CM_ "AUTOGENERATED FILE, DO NOT EDIT";

CM_ "Imported file _toyota_2017.dbc starts here";
VERSION ""

NS_ :

BS_:

BU_: XXX DSU HCU EPS IPAS CGW BGM

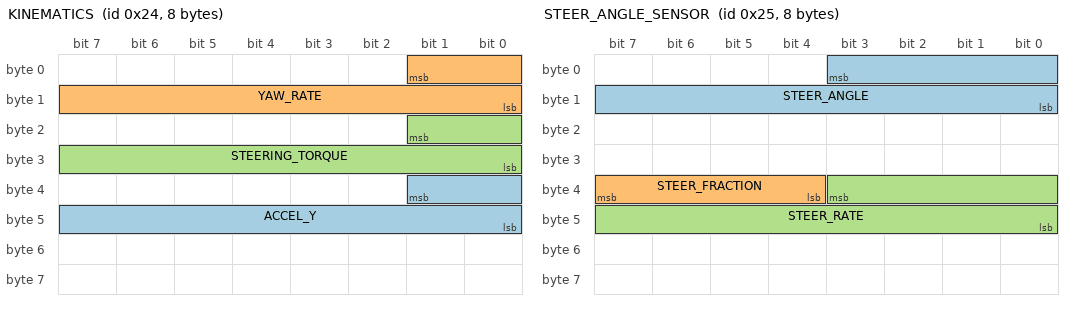
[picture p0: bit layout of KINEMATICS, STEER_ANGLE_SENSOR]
BO_ 36 KINEMATICS: 8 XXX
 SG_ ACCEL_Y : 33|10@0+ (0.03589,-18.375) [0|65535] "m/s^2" XXX
 SG_ YAW_RATE : 1|10@0+ (0.244,-125) [0|65535] "deg/s" XXX
 SG_ STEERING_TORQUE : 17|10@0+ (1,-512) [0|65535] "" XXX

BO_ 37 STEER_ANGLE_SENSOR: 8 XXX
 SG_ STEER_ANGLE : 3|12@0- (1.5,0) [-500|500] "deg" XXX
 SG_ STEER_FRACTION : 39|4@0- (0.1,0) [-0.7|0.7] "deg" XXX
 SG_ STEER_RATE : 35|12@0- (1,0) [-2000|2000] "deg/s" XXX

BO_ 166 BRAKE: 8 XXX
 SG_ BRAKE_AMOUNT : 7|8@0+ (1,0) [0|255] "" XXX
 SG_ BRAKE_PEDAL : 23|8@0+ (1,0) [0|255] "" XXX

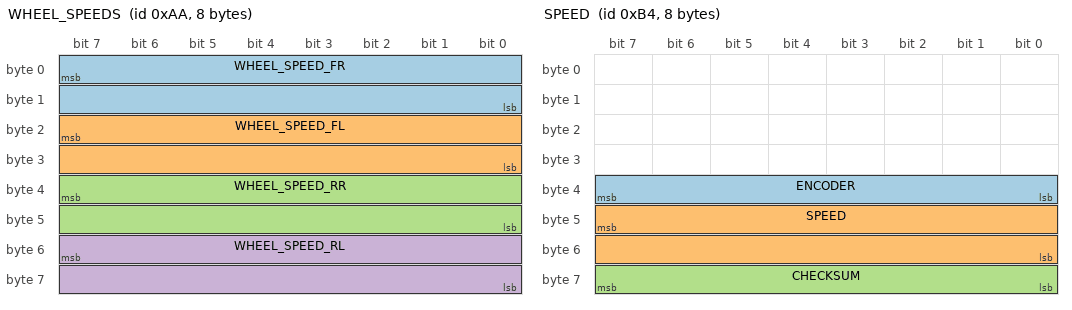
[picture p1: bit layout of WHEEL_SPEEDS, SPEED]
BO_ 170 WHEEL_SPEEDS: 8 XXX
 SG_ WHEEL_SPEED_FR : 7|16@0+ (0.01,-67.67) [0|250] "km/h" XXX
 SG_ WHEEL_SPEED_FL : 23|16@0+ (0.01,-67.67) [0|250] "km/h" XXX
 SG_ WHEEL_SPEED_RR : 39|16@0+ (0.01,-67.67) [0|250] "km/h" XXX
 SG_ WHEEL_SPEED_RL : 55|16@0+ (0.01,-67.67) [0|250] "km/h" XXX

BO_ 180 SPEED: 8 XXX
 SG_ ENCODER : 39|8@0+ (1,0) [0|255] "" XXX
 SG_ SPEED : 47|16@0+ (0.01,0) [0|250] "km/h" XXX
 SG_ CHECKSUM : 63|8@0+ (1,0) [0|255] "" XXX

BO_ 353 DSU_SPEED: 7 XXX
 SG_ FORWARD_SPEED : 15|16@0- (0.00390625,-30) [0|255] "km/h" XXX

BO_ 452 ENGINE_RPM: 8 CGW
 SG_ RPM : 7|16@0- (0.78125,0) [0|0] "rpm" SCS

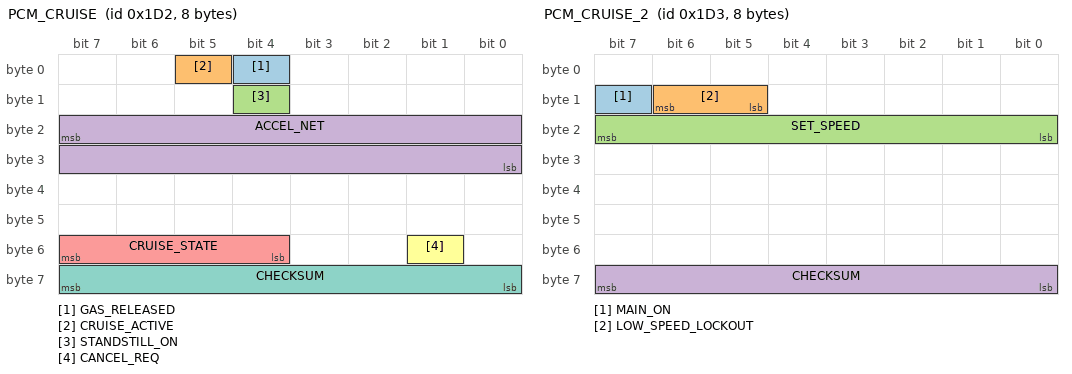
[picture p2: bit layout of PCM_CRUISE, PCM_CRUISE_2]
BO_ 466 PCM_CRUISE: 8 XXX
 SG_ GAS_RELEASED : 4|1@0+ (1,0) [0|1] "" XXX
 SG_ CRUISE_ACTIVE : 5|1@0+ (1,0) [0|1] "" XXX
 SG_ STANDSTILL_ON : 12|1@0+ (1,0) [0|1] "" XXX
 SG_ ACCEL_NET : 23|16@0- (0.001,0) [-20|20] "m/s^2" XXX
 SG_ CRUISE_STATE : 55|4@0+ (1,0) [0|15] "" XXX
 SG_ CANCEL_REQ : 49|1@1+ (1,0) [0|1] "" XXX
 SG_ CHECKSUM : 63|8@0+ (1,0) [0|255] "" XXX

BO_ 467 PCM_CRUISE_2: 8 XXX
 SG_ MAIN_ON : 15|1@0+ (1,0) [0|1] "" XXX
 SG_ LOW_SPEED_LOCKOUT : 14|2@0+ (1,0) [0|3] "" XXX
 SG_ SET_SPEED : 23|8@0+ (1,0) [0|255] "km/h" XXX
 SG_ CHECKSUM : 63|8@0+ (1,0) [0|255] "" XXX

BO_ 552 ACCELEROMETER: 8 XXX
 SG_ ACCEL_Z : 22|15@0- (1,0) [0|32767] "m/s^2" XXX
 SG_ ACCEL_X : 6|15@0- (0.001,0) [-20|20] "m/s^2" XXX

BO_ 560 BRAKE_2: 7 XXX
 SG_ BRAKE_PRESSED : 26|1@0+ (1,0) [0|1] "" XXX

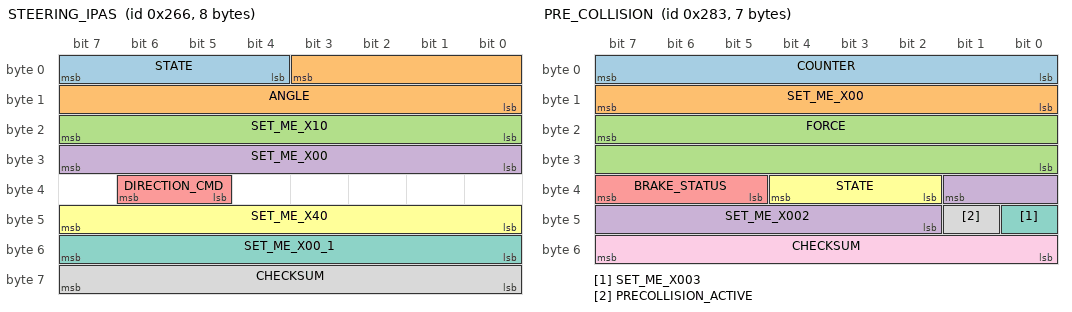
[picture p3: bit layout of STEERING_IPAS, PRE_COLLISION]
BO_ 614 STEERING_IPAS: 8 IPAS
 SG_ STATE : 7|4@0+ (1,0) [0|15] "" XXX
 SG_ ANGLE : 3|12@0- (1.5,0) [-510|510] "deg" XXX
 SG_ SET_ME_X10 : 23|8@0+ (1,0) [0|255] "" XXX
 SG_ SET_ME_X00 : 31|8@0+ (1,0) [0|255] "" XXX
 SG_ DIRECTION_CMD : 38|2@0+ (1,0) [0|3] "" XXX
 SG_ SET_ME_X40 : 47|8@0+ (1,0) [0|255] "" XXX
 SG_ SET_ME_X00_1 : 55|8@0+ (1,0) [0|255] "" XXX
 SG_ CHECKSUM : 63|8@0+ (1,0) [0|255] "" XXX

BO_ 643 PRE_COLLISION: 7 DSU
 SG_ COUNTER : 7|8@0+ (1,0) [0|255] "" XXX
 SG_ SET_ME_X00 : 15|8@0+ (1,0) [0|255] "" XXX
 SG_ FORCE : 23|16@0- (2,0) [0|255] "N" XXX
 SG_ SET_ME_X002 : 33|8@0+ (1,0) [0|3] "" XXX
 SG_ BRAKE_STATUS : 39|3@0+ (1,0) [0|255] "" XXX
 SG_ STATE : 36|3@0+ (1,0) [0|255] "" XXX
 SG_ SET_ME_X003 : 40|1@0+ (1,0) [0|1] "" XXX
 SG_ PRECOLLISION_ACTIVE : 41|1@0+ (1,0) [0|255] "" XXX
 SG_ CHECKSUM : 55|8@0+ (1,0) [0|255] "" XXX

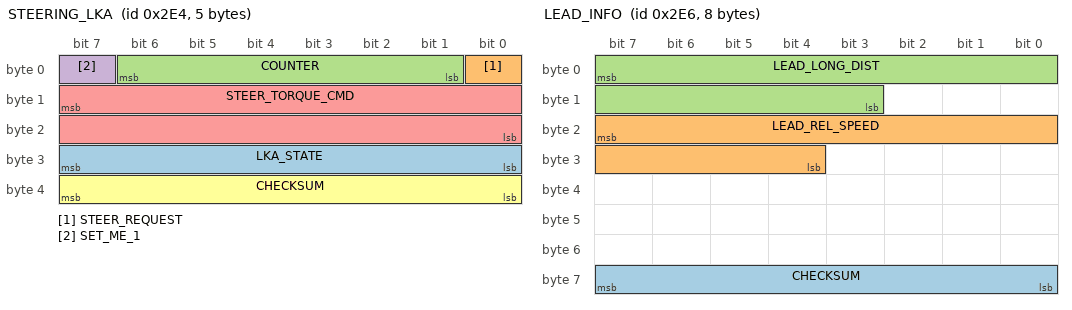
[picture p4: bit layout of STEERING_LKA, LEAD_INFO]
BO_ 740 STEERING_LKA: 5 XXX
 SG_ LKA_STATE : 31|8@0+ (1,0) [0|255] "" XXX
 SG_ STEER_REQUEST : 0|1@0+ (1,0) [0|1] "" XXX
 SG_ COUNTER : 6|6@0+ (1,0) [0|63] "" XXX
 SG_ SET_ME_1 : 7|1@0+ (1,0) [0|1] "" XXX
 SG_ STEER_TORQUE_CMD : 15|16@0- (1,0) [0|65535] "" XXX
 SG_ CHECKSUM : 39|8@0+ (1,0) [0|255] "" XXX

BO_ 742 LEAD_INFO: 8 DSU
 SG_ CHECKSUM : 63|8@0+ (1,0) [0|255] "" HCU
 SG_ LEAD_REL_SPEED : 23|12@0- (0.025,0) [-100|100] "m/s" HCU
 SG_ LEAD_LONG_DIST : 7|13@0+ (0.05,0) [0|300] "m" HCU

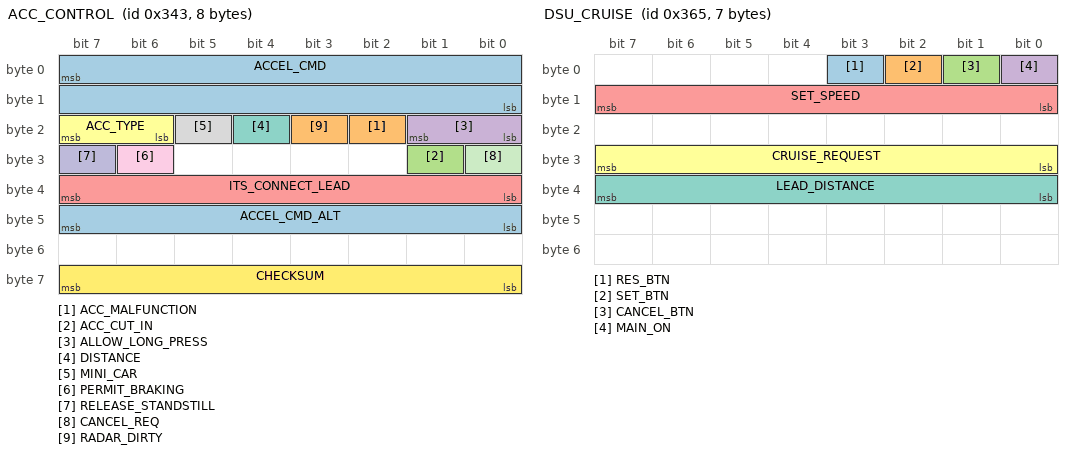
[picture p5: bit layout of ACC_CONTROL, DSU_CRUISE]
BO_ 835 ACC_CONTROL: 8 DSU
 SG_ ACCEL_CMD : 7|16@0- (0.001,0) [-20|20] "m/s^2" HCU
 SG_ ACC_MALFUNCTION : 18|1@0+ (1,0) [0|0] "" XXX
 SG_ ACC_CUT_IN : 25|1@0+ (1,0) [0|1] "" XXX
 SG_ ALLOW_LONG_PRESS : 17|2@0+ (1,0) [0|2] "" XXX
 SG_ ITS_CONNECT_LEAD : 39|8@0+ (1,0) [0|1] "" Vector__XXX
 SG_ ACC_TYPE : 23|2@0+ (1,0) [0|3] "" HCU
 SG_ DISTANCE : 20|1@0+ (1,0) [0|1] "" XXX
 SG_ MINI_CAR : 21|1@0+ (1,0) [0|1] "" XXX
 SG_ PERMIT_BRAKING : 30|1@0+ (1,0) [0|1] "" HCU
 SG_ RELEASE_STANDSTILL : 31|1@0+ (1,0) [0|1] "" HCU
 SG_ CANCEL_REQ : 24|1@0+ (1,0) [0|1] "" HCU
 SG_ CHECKSUM : 63|8@0+ (1,0) [0|255] "" XXX
 SG_ ACCEL_CMD_ALT : 47|8@0- (0.05,0) [0|0] "m/s^2" XXX
 SG_ RADAR_DIRTY : 19|1@0+ (1,0) [0|1] "" XXX

BO_ 836 PRE_COLLISION_2: 8 DSU
 SG_ CHECKSUM : 63|8@0+ (1,0) [0|0] "" XXX

BO_ 869 DSU_CRUISE : 7 DSU
 SG_ RES_BTN : 3|1@0+ (1,0) [0|0] "" XXX
 SG_ SET_BTN : 2|1@0+ (1,0) [0|0] "" XXX
 SG_ CANCEL_BTN : 1|1@0+ (1,0) [0|0] "" XXX
 SG_ MAIN_ON : 0|1@0+ (1,0) [0|0] "" XXX
 SG_ SET_SPEED : 15|8@0+ (1,0) [0|0] "km/h" XXX
 SG_ CRUISE_REQUEST : 31|8@0+ (100,-12800) [0|0] "N" XXX
 SG_ LEAD_DISTANCE : 39|8@0+ (1,0) [0|0] "m" XXX

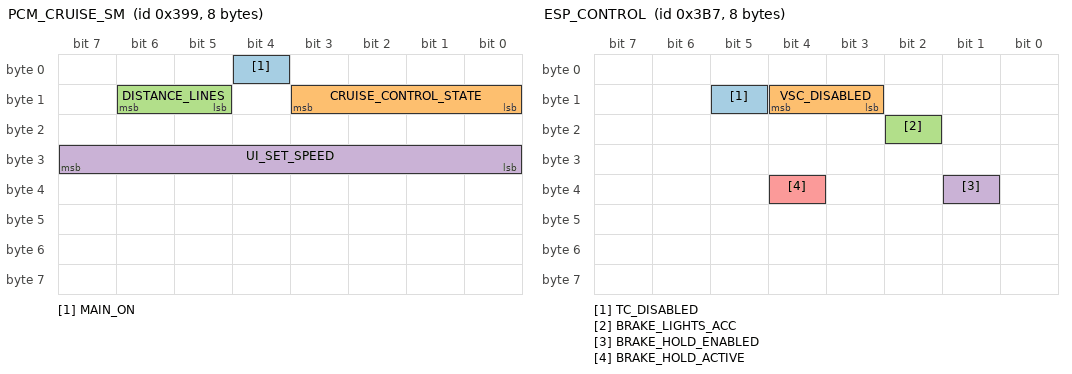
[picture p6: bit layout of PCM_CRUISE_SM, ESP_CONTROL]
BO_ 921 PCM_CRUISE_SM: 8 XXX
 SG_ MAIN_ON : 4|1@0+ (1,0) [0|1] "" XXX
 SG_ CRUISE_CONTROL_STATE : 11|4@0+ (1,0) [0|15] "" XXX
 SG_ DISTANCE_LINES : 14|2@0+ (1,0) [0|3] "" XXX
 SG_ UI_SET_SPEED : 31|8@0+ (1,0) [0|255] "" XXX

BO_ 951 ESP_CONTROL: 8 ESP
 SG_ TC_DISABLED : 13|1@0+ (1,0) [0|1] "" XXX
 SG_ VSC_DISABLED : 12|2@0+ (1,0) [0|1] "" XXX
 SG_ BRAKE_LIGHTS_ACC : 18|1@0+ (1,0) [0|1] "" XXX
 SG_ BRAKE_HOLD_ENABLED : 33|1@1+ (1,0) [0|1] "" XXX
 SG_ BRAKE_HOLD_ACTIVE : 36|1@0+ (1,0) [0|1] "" XXX

BO_ 1005 REVERSE_CAMERA_STATE: 2 BGM
 SG_ REVERSE_CAMERA_GUIDELINES : 9|2@0+ (1,0) [1|3] "" XXX

BO_ 1020 SOLAR_SENSOR: 8 XXX
 SG_ LUX_SENSOR : 55|13@0+ (1,0) [0|0] "" XXX

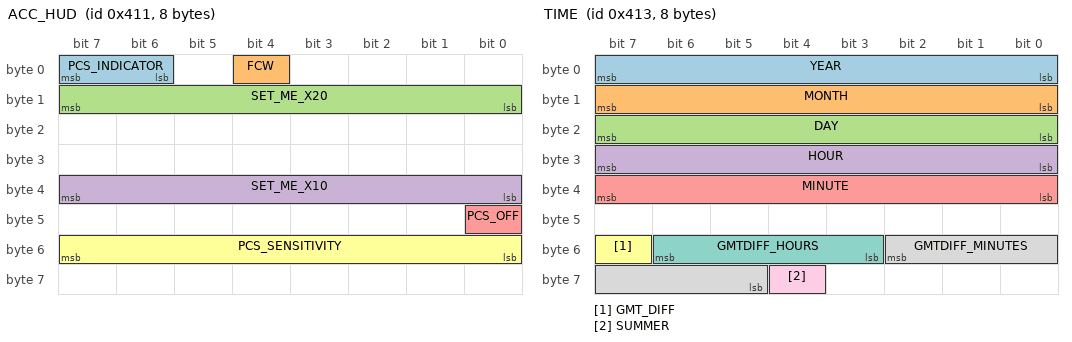
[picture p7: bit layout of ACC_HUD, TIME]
BO_ 1041 ACC_HUD: 8 DSU
 SG_ PCS_INDICATOR : 7|2@0+ (1,0) [0|3] "" XXX
 SG_ FCW : 4|1@0+ (1,0) [0|1] "" XXX
 SG_ SET_ME_X20 : 15|8@0+ (1,0) [0|1] "" XXX
 SG_ SET_ME_X10 : 39|8@0+ (1,0) [0|1] "" XXX
 SG_ PCS_OFF : 40|1@0+ (1,0) [0|0] "" XXX
 SG_ PCS_SENSITIVITY : 55|8@0+ (1,0) [0|1] "" XXX

BO_ 1042 LKAS_HUD: 8 DSU
 SG_ BARRIERS : 1|2@0+ (1,0) [0|3] "" XXX
 SG_ RIGHT_LINE : 3|2@0+ (1,0) [0|3] "" XXX
 SG_ LEFT_LINE : 5|2@0+ (1,0) [0|3] "" XXX
 SG_ LKAS_STATUS : 7|2@0+ (1,0) [0|3] "" XXX
 SG_ LDA_ALERT : 9|2@0+ (1,0) [0|3] "" XXX
 SG_ LDW_EXIST : 10|1@0+ (1,0) [0|1] "" XXX
 SG_ TWO_BEEPS : 12|1@0+ (1,0) [0|1] "" XXX
 SG_ ADJUSTING_CAMERA : 13|1@0+ (1,0) [0|1] "" XXX
 SG_ LDA_UNAVAILABLE_QUIET : 14|1@0+ (1,0) [0|1] "" XXX
 SG_ LDA_MALFUNCTION : 15|1@0+ (1,0) [0|1] "" XXX
 SG_ LDA_UNAVAILABLE : 16|1@0+ (1,0) [0|1] "" XXX
 SG_ LDA_SENSITIVITY : 18|2@0+ (1,0) [0|3] "" XXX
 SG_ LDA_SA_TOGGLE : 20|2@0+ (1,0) [0|3] "" XXX
 SG_ LDA_SPEED_TOO_LOW : 21|1@0+ (1,0) [0|1] "" XXX
 SG_ LDA_ON_MESSAGE : 31|2@0+ (1,0) [0|3] "" XXX
 SG_ REPEATED_BEEPS : 32|1@0+ (1,0) [0|1] "" XXX
 SG_ LANE_SWAY_TOGGLE : 43|1@0+ (1,0) [0|1] "" XXX
 SG_ LANE_SWAY_SENSITIVITY : 45|2@0+ (1,0) [0|3] "" XXX
 SG_ TAKE_CONTROL : 46|1@0+ (1,0) [0|1] "" XXX
 SG_ LDA_FRONT_CAMERA_BLOCKED : 47|1@0+ (1,0) [0|1] "" XXX
 SG_ LANE_SWAY_BUZZER : 50|2@0+ (1,0) [0|0] "" XXX
 SG_ LANE_SWAY_FLD : 53|3@0+ (1,0) [0|7] "" XXX
 SG_ LANE_SWAY_WARNING : 55|2@0+ (1,0) [0|3] "" XXX
 SG_ SET_ME_X01 : 42|1@0+ (1,0) [0|1] "" XXX
 SG_ SET_ME_X02 : 63|8@0+ (1,0) [0|1] "" XXX

BO_ 1043 TIME : 8 CGW
 SG_ YEAR : 7|8@0+ (1,0) [0|0] "year" XXX
 SG_ MONTH : 15|8@0+ (1,0) [0|0] "month" XXX
 SG_ DAY : 23|8@0+ (1,0) [0|0] "day" XXX
 SG_ HOUR : 31|8@0+ (1,0) [0|0] "hour" XXX
 SG_ MINUTE : 39|8@0+ (1,0) [0|0] "minute" XXX
 SG_ GMT_DIFF : 55|1@0+ (1,0) [0|0] "" XXX
 SG_ GMTDIFF_HOURS : 54|4@0+ (1,0) [0|0] "hours" XXX
 SG_ GMTDIFF_MINUTES : 50|6@0+ (1,0) [0|0] "minutes" XXX
 SG_ SUMMER : 60|1@0+ (1,0) [0|0] "" XXX

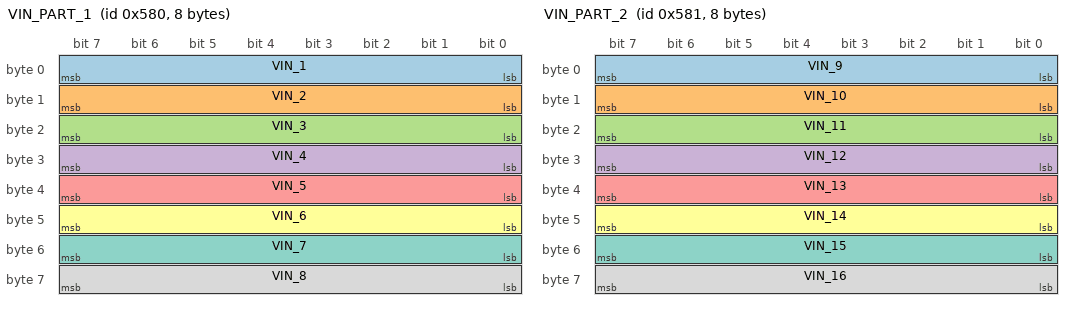
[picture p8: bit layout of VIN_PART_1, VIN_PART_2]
BO_ 1408 VIN_PART_1: 8 CGW
 SG_ VIN_1 : 7|8@0+ (1,0) [0|0] "" XXX
 SG_ VIN_2 : 15|8@0+ (1,0) [0|0] "" XXX
 SG_ VIN_3 : 23|8@0+ (1,0) [0|0] "" XXX
 SG_ VIN_4 : 31|8@0+ (1,0) [0|0] "" XXX
 SG_ VIN_5 : 39|8@0+ (1,0) [0|0] "" XXX
 SG_ VIN_6 : 47|8@0+ (1,0) [0|0] "" XXX
 SG_ VIN_7 : 55|8@0+ (1,0) [0|0] "" XXX
 SG_ VIN_8 : 63|8@0+ (1,0) [0|0] "" XXX

BO_ 1409 VIN_PART_2: 8 CGW
 SG_ VIN_9 : 7|8@0+ (1,0) [0|0] "" XXX
 SG_ VIN_10 : 15|8@0+ (1,0) [0|0] "" XXX
 SG_ VIN_11 : 23|8@0+ (1,0) [0|0] "" XXX
 SG_ VIN_12 : 31|8@0+ (1,0) [0|0] "" XXX
 SG_ VIN_13 : 39|8@0+ (1,0) [0|0] "" XXX
 SG_ VIN_14 : 47|8@0+ (1,0) [0|0] "" XXX
 SG_ VIN_15 : 55|8@0+ (1,0) [0|0] "" XXX
 SG_ VIN_16 : 63|8@0+ (1,0) [0|0] "" XXX

BO_ 1410 VIN_PART_3: 8 CGW
 SG_ VIN_17 : 7|8@0+ (1,0) [0|0] "" XXX

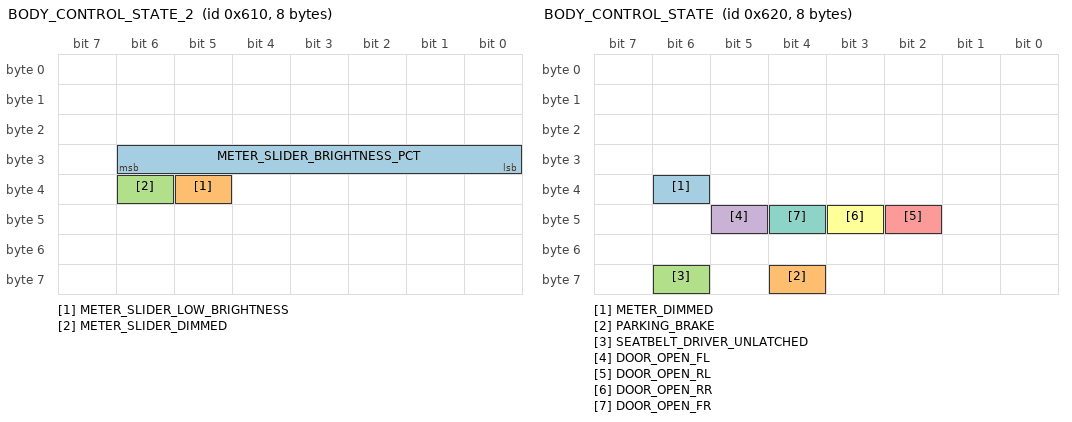
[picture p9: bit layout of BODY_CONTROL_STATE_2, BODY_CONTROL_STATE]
BO_ 1552 BODY_CONTROL_STATE_2: 8 XXX
 SG_ METER_SLIDER_BRIGHTNESS_PCT : 30|7@0+ (1,0) [12|100] "%" XXX
 SG_ METER_SLIDER_LOW_BRIGHTNESS : 37|1@0+ (1,0) [0|1] "" XXX
 SG_ METER_SLIDER_DIMMED : 38|1@0+ (1,0) [0|1] "" XXX

BO_ 1553 UI_SETTING: 8 XXX
 SG_ UNITS : 26|2@0+ (1,0) [0|3] "" XXX
 SG_ ODOMETER : 43|20@0+ (1,0) [0|1048575] "" XXX

BO_ 1556 BLINKERS_STATE: 8 XXX
 SG_ TURN_SIGNALS : 29|2@0+ (1,0) [0|3] "" XXX
 SG_ HAZARD_LIGHT : 27|1@0+ (1,0) [0|1] "" XXX

BO_ 1568 BODY_CONTROL_STATE: 8 XXX
 SG_ METER_DIMMED : 38|1@0+ (1,0) [0|1] "" XXX
 SG_ PARKING_BRAKE : 60|1@0+ (1,0) [0|1] "" XXX
 SG_ SEATBELT_DRIVER_UNLATCHED : 62|1@0+ (1,0) [0|1] "" XXX
 SG_ DOOR_OPEN_FL : 45|1@0+ (1,0) [0|1] "" XXX
 SG_ DOOR_OPEN_RL : 42|1@0+ (1,0) [0|1] "" XXX
 SG_ DOOR_OPEN_RR : 43|1@0+ (1,0) [0|1] "" XXX
 SG_ DOOR_OPEN_FR : 44|1@0+ (1,0) [0|1] "" XXX

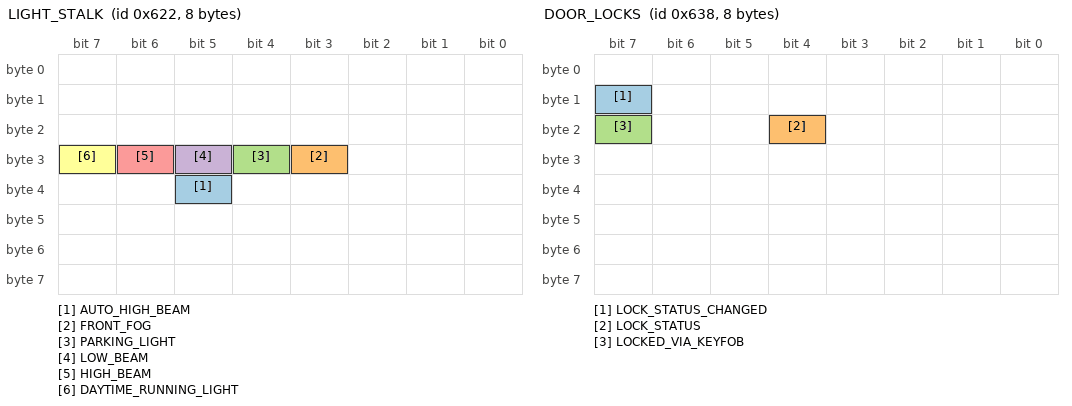
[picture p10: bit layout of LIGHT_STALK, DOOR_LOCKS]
BO_ 1570 LIGHT_STALK: 8 SCM
 SG_ AUTO_HIGH_BEAM : 37|1@0+ (1,0) [0|1] "" XXX
 SG_ FRONT_FOG : 27|1@0+ (1,0) [0|1] "" XXX
 SG_ PARKING_LIGHT : 28|1@0+ (1,0) [0|1] "" XXX
 SG_ LOW_BEAM : 29|1@0+ (1,0) [0|1] "" XXX
 SG_ HIGH_BEAM : 30|1@0+ (1,0) [0|1] "" XXX
 SG_ DAYTIME_RUNNING_LIGHT : 31|1@0+ (1,0) [0|1] "" XXX

BO_ 1592 DOOR_LOCKS: 8 XXX
 SG_ LOCK_STATUS_CHANGED : 15|1@0+ (1,0) [0|1] "" XXX
 SG_ LOCK_STATUS : 20|1@0+ (1,0) [0|1] "" XXX
 SG_ LOCKED_VIA_KEYFOB : 23|1@0+ (1,0) [0|1] "" XXX

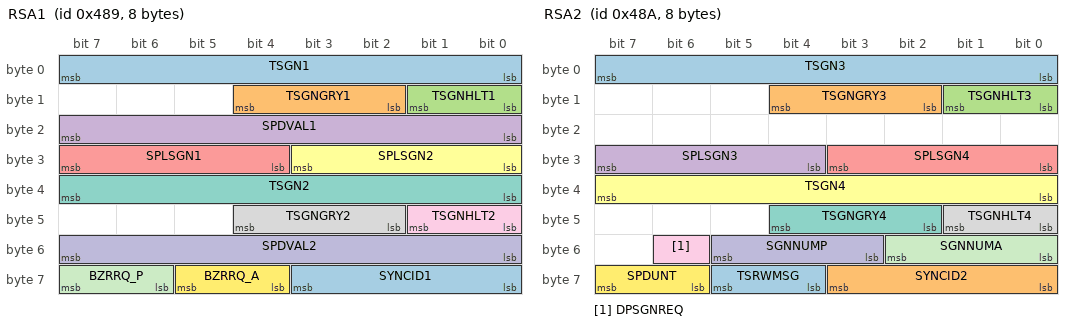
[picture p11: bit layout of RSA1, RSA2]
BO_ 1161 RSA1: 8 FCM
 SG_ TSGN1 : 7|8@0+ (1,0) [0|0] "" XXX
 SG_ TSGNGRY1 : 12|3@0+ (1,0) [0|0] "" XXX
 SG_ TSGNHLT1 : 9|2@0+ (1,0) [0|0] "" XXX
 SG_ SPDVAL1 : 23|8@0+ (1,0) [0|0] "km/h" XXX
 SG_ SPLSGN1 : 31|4@0+ (1,0) [0|0] "" XXX
 SG_ SPLSGN2 : 27|4@0+ (1,0) [0|0] "" XXX
 SG_ TSGN2 : 39|8@0+ (1,0) [0|0] "" XXX
 SG_ TSGNGRY2 : 44|3@0+ (1,0) [0|0] "" XXX
 SG_ TSGNHLT2 : 41|2@0+ (1,0) [0|0] "" XXX
 SG_ SPDVAL2 : 55|8@0+ (1,0) [0|0] "" XXX
 SG_ BZRRQ_P : 63|2@0+ (1,0) [0|0] "" XXX
 SG_ BZRRQ_A : 61|2@0+ (1,0) [0|0] "" XXX
 SG_ SYNCID1 : 59|4@0+ (1,0) [0|0] "" XXX

BO_ 1162 RSA2: 8 FCM
 SG_ TSGN3 : 7|8@0+ (1,0) [0|0] "" XXX
 SG_ TSGNGRY3 : 12|3@0+ (1,0) [0|0] "" XXX
 SG_ TSGNHLT3 : 9|2@0+ (1,0) [0|0] "" XXX
 SG_ SPLSGN3 : 31|4@0+ (1,0) [0|0] "" XXX
 SG_ SPLSGN4 : 27|4@0+ (1,0) [0|0] "" XXX
 SG_ TSGN4 : 39|8@0+ (1,0) [0|0] "" XXX
 SG_ TSGNGRY4 : 44|3@0+ (1,0) [0|0] "" XXX
 SG_ TSGNHLT4 : 41|2@0+ (1,0) [0|0] "" XXX
 SG_ DPSGNREQ : 54|1@0+ (1,0) [0|0] "" XXX
 SG_ SGNNUMP : 53|3@0+ (1,0) [0|0] "" XXX
 SG_ SGNNUMA : 50|3@0+ (1,0) [0|0] "" XXX
 SG_ SPDUNT : 63|2@0+ (1,0) [0|0] "" XXX
 SG_ TSRWMSG : 61|2@0+ (1,0) [0|0] "" XXX
 SG_ SYNCID2 : 59|4@0+ (1,0) [0|0] "" XXX

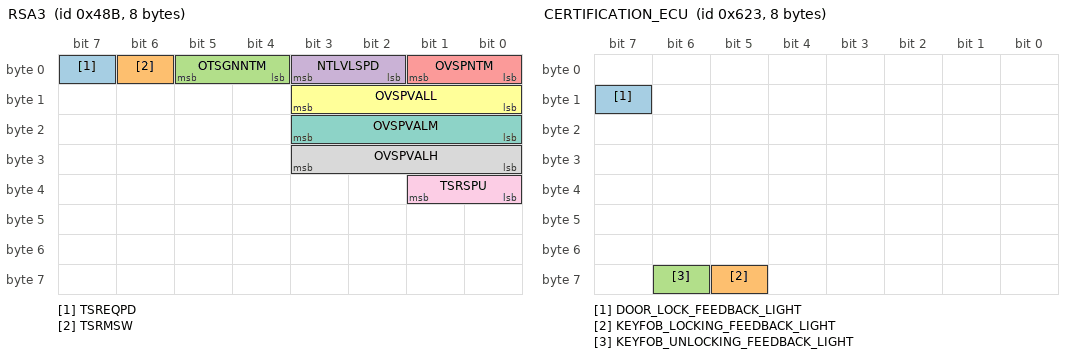
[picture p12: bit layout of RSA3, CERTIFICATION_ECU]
BO_ 1163 RSA3: 8 FCM
 SG_ TSREQPD : 7|1@0+ (1,0) [0|0] "" XXX
 SG_ TSRMSW : 6|1@0+ (1,0) [0|0] "" XXX
 SG_ OTSGNNTM : 5|2@0+ (1,0) [0|0] "" XXX
 SG_ NTLVLSPD : 3|2@0+ (1,0) [0|0] "" XXX
 SG_ OVSPNTM : 1|2@0+ (1,0) [0|0] "" XXX
 SG_ OVSPVALL : 11|4@0+ (1,-5) [0|0] "" XXX
 SG_ OVSPVALM : 19|4@0+ (1,-5) [0|0] "" XXX
 SG_ OVSPVALH : 27|4@0+ (1,-5) [0|0] "" XXX
 SG_ TSRSPU : 33|2@0+ (1,0) [0|0] "" XXX

BO_ 1571 CERTIFICATION_ECU: 8 CGW
 SG_ DOOR_LOCK_FEEDBACK_LIGHT : 15|1@0+ (1,0) [0|0] "" XXX
 SG_ KEYFOB_LOCKING_FEEDBACK_LIGHT : 61|1@0+ (1,0) [0|0] "" XXX
 SG_ KEYFOB_UNLOCKING_FEEDBACK_LIGHT : 62|1@0+ (1,0) [0|0] "" XXX

CM_ SG_ 36 YAW_RATE "verify";
CM_ SG_ 36 STEERING_TORQUE "does not seem the steer torque, tbd";
CM_ SG_ 37 STEER_FRACTION "1/15th of the signal STEER_ANGLE, which is 1.5 deg; note that 0x8 is never set";
CM_ SG_ 37 STEER_RATE "factor is tbd";
CM_ SG_ 466 ACCEL_NET "net acceleration produced by the system, given ACCEL_CMD, road grade and other factors";
CM_ SG_ 466 CRUISE_STATE "Active state is 8, if standstill is requested will switch to state 11(3 sec timer), after timer is elapsed will switch into state 7(standstill). If plus button was pressed - status 9, minus button pressed - status 10";
CM_ SG_ 467 SET_SPEED "43 km/h are shown as 28 mph, so conversion isn't perfect";
CM_ SG_ 467 LOW_SPEED_LOCKOUT "in low speed lockout, system would always disengage below 28mph";
CM_ SG_ 560 BRAKE_PRESSED "another brake pressed?";
CM_ SG_ 608 STEER_TORQUE_DRIVER "driver torque";
CM_ SG_ 608 STEER_OVERRIDE "set when driver torque exceeds a certain value";
CM_ SG_ 614 ANGLE "set to measured angle when ipas control isn't active";
CM_ SG_ 643 COUNTER "only used on cars that use this msg for cruise control";
CM_ SG_ 643 BRAKE_STATUS "only used on cars that use this msg for cruise control";
CM_ SG_ 643 PRECOLLISION_ACTIVE "set 0.5s before any braking";
CM_ SG_ 835 ACC_TYPE "if 2, car is likely to have a permanent low speed lockout. 1 is ok";
CM_ SG_ 835 RADAR_DIRTY "Display Clean Radar Sensor message on HUD";
CM_ SG_ 835 ACC_MALFUNCTION "display ACC fault on dash if set to 1";
CM_ SG_ 835 ACC_CUT_IN "Display blinking yellow lead if set to 1";
CM_ SG_ 835 DISTANCE "Display Distance Bars on HUD Permanently";
CM_ SG_ 835 ITS_CONNECT_LEAD "Displayed when lead car is capable of ITS Connect";
CM_ SG_ 835 ALLOW_LONG_PRESS "Enable Toyota's factory set speed increment behaviour, available on both metrics cars and imperial unit cars";
CM_ SG_ 835 PERMIT_BRAKING "Original ACC has this going high when a car in front is detected. In openpilot and before the PERMIT_BRAKING name, this was 'SET_ME_1' and is hardcoded to be high. Unsure if only informational or has an effect though existing usage in openpilot is to always set it to 1. Originally 'PMTBRKG' in the leaked toyota_2017_ref_pt.dbc file and name expansion speculated to be PerMiT BRaKinG.";
CM_ SG_ 835 ACCEL_CMD_ALT "Copy of main ACCEL_CMD, but across 8 bits instead of 16 bits like ACCEL_CMD. Unsure if only informational or has an effect. Likely informational as existing openpilot sets this to 0 and no loss of functionality observed. Originally 'AT_RAW' in leaked toyota_2017_ref_pt.dbc file.";
CM_ SG_ 921 UI_SET_SPEED "set speed shown in UI with user set unit";
CM_ SG_ 951 BRAKE_LIGHTS_ACC "brake lights when ACC commands decel";
CM_ SG_ 1041 PCS_INDICATOR "Pre-Collision System Indicator";
CM_ SG_ 1041 PCS_SENSITIVITY "Pre-Collision System Sensitivity";
CM_ SG_ 1042 LDA_SA_TOGGLE "LDA Steering Assist Toggle";
CM_ SG_ 1042 LDW_EXIST "Unclear what this is, it's usually set to 0";
CM_ SG_ 1042 LDA_SENSITIVITY "LDA Sensitivity";
CM_ SG_ 1042 LDA_ON_MESSAGE "Display LDA Turned ON message";
CM_ SG_ 1042 REPEATED_BEEPS "LDA audible warning";
CM_ SG_ 1042 LDA_UNAVAILABLE_QUIET "LDA toggles and sensitivity settings are greyed out if set to 1";
CM_ SG_ 1042 LDA_SPEED_TOO_LOW "length is 3 bits in the leaked DBC, displays LDA unavailable below approx 50 km/h if set to 1";
CM_ SG_ 1042 LDA_FRONT_CAMERA_BLOCKED "originally LDAFCVB, LDA related settings are greyed out if set to 1";
CM_ SG_ 1042 TAKE_CONTROL "Please Control Steering Wheel warning";
CM_ SG_ 1042 LANE_SWAY_TOGGLE "Lane Sway Warning System SWS Switch";
CM_ SG_ 1042 LANE_SWAY_WARNING "Lane Sway Warning System Triggered";
CM_ SG_ 1042 LANE_SWAY_FLD "Unknown signal for Lane Sway Warning System, set to 7 on stock system when SWS is enabled, 0 when SWS is disabled";
CM_ SG_ 1042 LANE_SWAY_BUZZER "Similar to TWO_BEEPS";
CM_ SG_ 1042 SET_ME_X01 "empty bit on leaked dbc, always set to 1 during normal operations";
CM_ SG_ 1042 SET_ME_X02 "empty bit on leaked dbc, always set to 2 during normal operations";
CM_ SG_ 1161 SPDVAL1 "Numbers 0-199 is displayed, 200-254 displays circle without number and 255 is for no limit.";
CM_ SG_ 1161 SYNCID1 "counter from 1 to f at 1 Hz";
CM_ SG_ 1161 SPDVAL2 "conditional speed value 70";
CM_ SG_ 1162 SGNNUMP "1 if SPDVAL1 is set, otherwise 0";
CM_ SG_ 1162 SYNCID2 "counter from 1 to f at 1 Hz";
CM_ SG_ 1163 TSREQPD "always 1";
CM_ SG_ 1163 TSRMSW "always 1";
CM_ SG_ 1163 OTSGNNTM "always 3";
CM_ SG_ 1163 NTLVLSPD "always 3";
CM_ SG_ 1163 OVSPNTM "always 3";
CM_ SG_ 1163 OVSPVALL "-5 at start then 2 after 2 seconds";
CM_ SG_ 1163 OVSPVALM "-5 at start then 5 after 2 seconds";
CM_ SG_ 1163 OVSPVALH "-5 at start then 10 after 2 seconds";
CM_ SG_ 1163 TSRSPU "always 1";
CM_ SG_ 1552 METER_SLIDER_BRIGHTNESS_PCT "Combination display brightness setting, scales from 12 per cent to 100 per cent, reflects combination meter settings only, not linked with headlight state";
CM_ SG_ 1552 METER_SLIDER_LOW_BRIGHTNESS "Combination display low brightness mode, also controls footwell lighting";
CM_ SG_ 1552 METER_SLIDER_DIMMED "Combination display slider not at max, reflects combination meter settings only, not linked with headlight state";
CM_ SG_ 1553 ODOMETER "Unit is dependent upon units signal";
CM_ SG_ 1592 LOCK_STATUS_CHANGED "1 on rising edge of lock/unlocking";
CM_ SG_ 1592 LOCKED_VIA_KEYFOB "1 for as long as locked with key fob";

VAL_ 466 CRUISE_STATE 11 "timer_3sec" 10 "adaptive click down" 9 "adaptive click up" 8 "adaptive engaged" 7 "standstill" 6 "non-adaptive click up" 5 "non-adaptive click down" 4 "non-adaptive hold down" 3 "non-adaptive hold up" 2 "non-adaptive being engaged" 1 "non-adaptive engaged" 0 "off";
VAL_ 467 LOW_SPEED_LOCKOUT 2 "low speed locked" 1 "ok";
VAL_ 614 STATE 3 "enabled" 1 "disabled";
VAL_ 614 DIRECTION_CMD 3 "right" 2 "center" 1 "left";
VAL_ 643 STATE 0 "normal" 1 "adaptive_cruise_control" 3 "emergency_braking";
VAL_ 835 ACC_TYPE 2 "permanent low speed lockout" 1 "ok";
VAL_ 835 ACC_MALFUNCTION 1 "faulted" 0 "ok";
VAL_ 835 ACC_CUT_IN 1 "CUT-IN Detected" 0 "clear";
VAL_ 835 ALLOW_LONG_PRESS 2 "set speed increase by 5 speed units regardless" 1 "set speed increase by 1 speed unit on short press, 5 speed units on long press";
VAL_ 921 CRUISE_CONTROL_STATE 2 "disabled" 11 "hold" 10 "hold_waiting_user_cmd" 6 "enabled" 5 "faulted";
VAL_ 1005 REVERSE_CAMERA_GUIDELINES 3 "No guidelines" 2 "Static guidelines" 1 "Active guidelines";
VAL_ 1041 PCS_INDICATOR 2 "PCS Faulted" 1 "PCS Turned Off By User" 0 "PCS Enabled";
VAL_ 1041 PCS_SENSITIVITY 64 "high sensitivity"  128 "mid sensitivity" 192 "low sensitivity" 0 "off";
VAL_ 1042 LDA_ALERT 3 "hold with continuous beep" 2 "LDA unavailable" 1 "hold" 0 "none";
VAL_ 1042 BARRIERS 3 "left" 2 "right" 1 "both" 0 "none";
VAL_ 1042 RIGHT_LINE 3 "orange" 2 "faded" 1 "solid" 0 "none";
VAL_ 1042 LKAS_STATUS 1 "on" 0 "off";
VAL_ 1042 LEFT_LINE 3 "orange" 2 "faded" 1 "solid" 0 "none";
VAL_ 1042 LDA_ON_MESSAGE 2 "Lane Departure Alert Turned ON, Steering Assist Inactive" 1 "Lane Departure Alert Turned ON, Steering Assist Active" 0 "clear";
VAL_ 1042 LDA_SA_TOGGLE  2 "steering assist off" 1 "steering assist on";
VAL_ 1042 LDA_SENSITIVITY 2 "standard" 1 "high" 0 "undefined";
VAL_ 1042 LDA_SPEED_TOO_LOW 1 "lda unavailable, speed too low" 0 "ok";
VAL_ 1042 LDA_FRONT_CAMERA_BLOCKED 1 "lda unavailable" 0 "ok";
VAL_ 1042 TAKE_CONTROL 1 "take control" 0 "ok";
VAL_ 1042 LANE_SWAY_WARNING 3 "ok" 2 "orange please take a break" 1 "prompt would you like to take a break" 0 "ok";
VAL_ 1042 LANE_SWAY_BUZZER 3 "ok" 2 "beep twice" 1 "beep twice" 0 "ok";
VAL_ 1553 UNITS 1 "km" 2 "miles";
VAL_ 1556 TURN_SIGNALS 3 "none" 2 "right" 1 "left";
VAL_ 1161 TSGN1 1 "speed sign" 0 "none";
VAL_ 1161 TSGN2 1 "speed sign" 0 "none";
VAL_ 1161 SPLSGN2 15 "conditional blank" 4 "wet road" 5 "rain" 0 "none";
VAL_ 1162 TSGN3 0 "none" 1 "speed sign" 2 "0 unlimited" 7 "unlimited" 16 "highway" 17 "no highway" 18 "motorway" 19 "no motorway" 20 "in city" 21 "outside city" 22 "pedestrian area" 23 "no pedestrian area" 65 "no overtaking left" 66 "no overtaking right" 67 "overtaking allowed again" 81 "no right turn" 97 "stop" 105 "yield" 113 "stop" 114 "yield us" 129 "no entry" 138 "no entry tss2" 145 "do not enter";
VAL_ 1162 SPLSGN3 15 "conditional blank" 4 "wet road" 5 "rain" 0 "none";
VAL_ 1552 METER_SLIDER_LOW_BRIGHTNESS 1 "Low brightness mode, footwell lights off" 0 "Normal mode, footwell lights on";
VAL_ 1552 METER_SLIDER_DIMMED 1 "Dimmed" 0 "Not Dimmed";
VAL_ 1592 LOCK_STATUS 0 "locked" 1 "unlocked";

CM_ "Imported file _comma.dbc starts here";
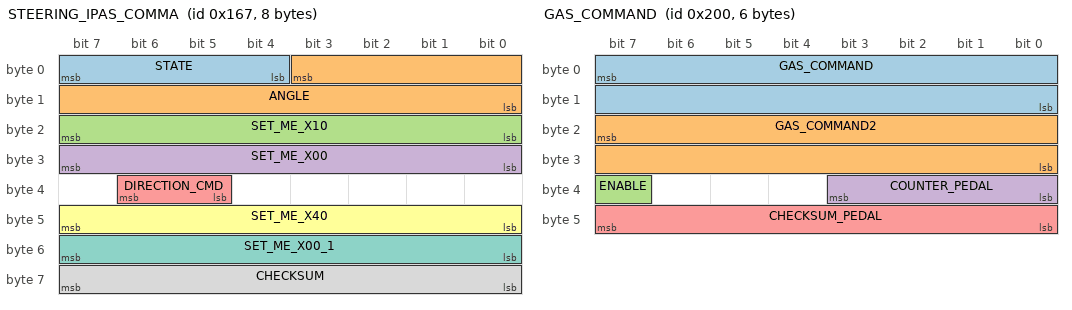
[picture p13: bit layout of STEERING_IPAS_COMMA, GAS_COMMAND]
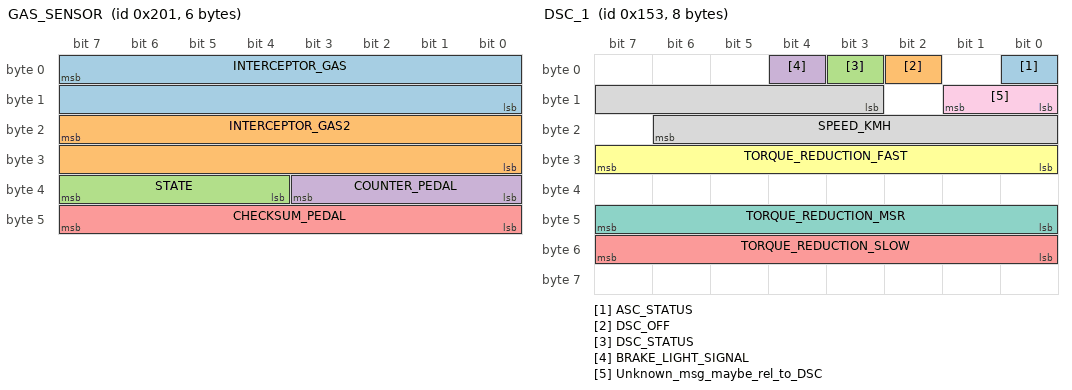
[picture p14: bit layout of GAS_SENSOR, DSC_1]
BO_ 359 STEERING_IPAS_COMMA: 8 IPAS
 SG_ STATE : 7|4@0+ (1,0) [0|15] "" XXX
 SG_ ANGLE : 3|12@0- (1.5,0) [-510|510] "deg" XXX
 SG_ SET_ME_X10 : 23|8@0+ (1,0) [0|255] "" XXX
 SG_ SET_ME_X00 : 31|8@0+ (1,0) [0|255] "" XXX
 SG_ DIRECTION_CMD : 38|2@0+ (1,0) [0|3] "" XXX
 SG_ SET_ME_X40 : 47|8@0+ (1,0) [0|255] "" XXX
 SG_ SET_ME_X00_1 : 55|8@0+ (1,0) [0|255] "" XXX
 SG_ CHECKSUM : 63|8@0+ (1,0) [0|255] "" XXX

CM_ "BO_ STEERING_IPAS_COMMA: Copy of msg 614 so we can do angle control while the Park Assist ECU is connected (Panda spoofs 614 with 359 on connector J70). Note that addresses 0x266 and 0x167 are checksum-invariant";

 BO_ 512 GAS_COMMAND: 6 EON
  SG_ GAS_COMMAND : 7|16@0+ (0.159375,-75.555) [0|1] "" INTERCEPTOR
  SG_ GAS_COMMAND2 : 23|16@0+ (0.159375,-151.111) [0|1] "" INTERCEPTOR
  SG_ ENABLE : 39|1@0+ (1,0) [0|1] "" INTERCEPTOR
  SG_ COUNTER_PEDAL : 35|4@0+ (1,0) [0|15] "" INTERCEPTOR
  SG_ CHECKSUM_PEDAL : 47|8@0+ (1,0) [0|255] "" INTERCEPTOR

 BO_ 513 GAS_SENSOR: 6 INTERCEPTOR
  SG_ INTERCEPTOR_GAS : 7|16@0+ (0.159375,-75.555) [0|1] "" EON
  SG_ INTERCEPTOR_GAS2 : 23|16@0+ (0.159375,-151.111) [0|1] "" EON
  SG_ STATE : 39|4@0+ (1,0) [0|15] "" EON
  SG_ COUNTER_PEDAL : 35|4@0+ (1,0) [0|15] "" EON
  SG_ CHECKSUM_PEDAL : 47|8@0+ (1,0) [0|255] "" EON

 VAL_ 513 STATE 5 "FAULT_TIMEOUT" 4 "FAULT_STARTUP" 3 "FAULT_SCE" 2 "FAULT_SEND" 1 "FAULT_BAD_CHECKSUM" 0 "NO_FAULT" ;

BO_ 35 SECONDARY_STEER_ANGLE: 8 XXX
 SG_ ZORRO_STEER : 7|24@0- (0.004901594652,0) [-500|500] "" XXX

CM_ "BO_ SECONDARY_STEER_ANGLE: ZSS is a high-precision steering angle sensor that can replace the lower resolution sensor in most TSS1 Toyotas. Learn more: https://github.com/commaai/openpilot/wiki/Toyota-Lexus#zorro-steering-sensor-zss";

BO_ 767 SDSU: 8 XXX
 SG_ FD_BUTTON : 7|1@0+ (1,0) [0|1] "" XXX

CM_ "BO_ SDSU: The sDSU is a modified DSU for use in TSS1 Toyotas. Learn more: https://github.com/wocsor/panda/tree/smart_dsu";

CM_ SG_ 767 FD_BUTTON "The follow distance button signal as forwarded by the sdsu";

CM_ "Imported file _bmw_e39_op.dbc starts here";
BO_ 339 DSC_1: 8 XXX
 SG_ ASC_STATUS : 0|1@1+ (1,0) [0|3] "" XXX
 SG_ DSC_OFF : 2|1@1+ (1,0) [0|3] "" XXX
 SG_ DSC_STATUS : 3|1@0+ (1,0) [0|3] "" XXX
 SG_ BRAKE_LIGHT_SIGNAL : 4|1@0+ (1,0) [0|3] "" XXX
 SG_ TORQUE_REDUCTION_SLOW : 55|8@0+ (1,0) [0|255] "" XXX
 SG_ TORQUE_REDUCTION_FAST : 31|8@0+ (1,0) [0|255] "" XXX
 SG_ TORQUE_REDUCTION_MSR : 47|8@0+ (1,0) [0|255] "" XXX
 SG_ SPEED_KMH : 11|12@1+ (0.0625,-2.64) [0|1] "kmh" XXX
 SG_ Unknown_msg_maybe_rel_to_DSC : 8|2@1+ (1,0) [0|3] "" XXX

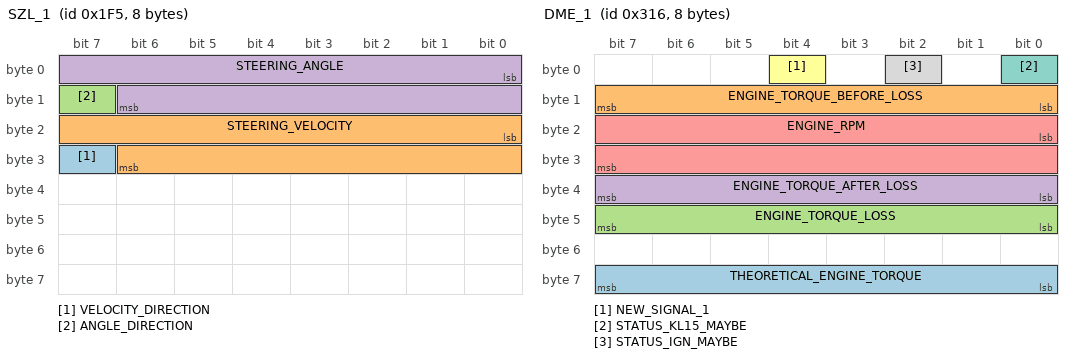
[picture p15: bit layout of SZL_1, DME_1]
BO_ 501 SZL_1: 8 XXX
 SG_ VELOCITY_DIRECTION : 31|1@0+ (1,0) [0|1] "" XXX
 SG_ STEERING_VELOCITY : 16|15@1+ (0.045,0) [0|1] "deg/s" XXX
 SG_ ANGLE_DIRECTION : 15|1@0+ (1,0) [0|1] "" XXX
 SG_ STEERING_ANGLE : 0|15@1+ (0.045,0) [0|1] "deg" XXX

BO_ 790 DME_1: 8 XXX
 SG_ THEORETICAL_ENGINE_TORQUE : 63|8@0+ (1,0) [0|65535] "" XXX
 SG_ ENGINE_TORQUE_BEFORE_LOSS : 8|8@1+ (1,0) [0|65535] "" XXX
 SG_ ENGINE_TORQUE_LOSS : 47|8@0+ (1,0) [0|255] "" XXX
 SG_ ENGINE_TORQUE_AFTER_LOSS : 39|8@0+ (1,0) [0|65535] "" XXX
 SG_ ENGINE_RPM : 16|16@1+ (0.15625,0) [0|65535] "" XXX
 SG_ NEW_SIGNAL_1 : 4|1@0+ (1,0) [0|3] "" XXX
 SG_ STATUS_KL15_MAYBE : 0|1@0+ (1,0) [0|1] "" XXX
 SG_ STATUS_IGN_MAYBE : 2|1@0+ (1,0) [0|1] "" XXX

BO_ 809 DME_2: 8 XXX
 SG_ CRUISE_CONTROL_REQUESTED_LOAD : 39|8@0+ (1,0) [0|255] "" XXX
 SG_ CRUISE_CONTROL_ENABLED : 51|1@0+ (1,0) [0|1] "" XXX
 SG_ BRAKE_LIGHT_SIGNAL_ERROR : 49|1@0+ (1,0) [0|1] "" XXX
 SG_ BRAKE_LIGHT_SIGNAL : 48|1@0+ (1,0) [0|1] "" XXX
 SG_ ATMOSPHERIC_PRESSURE : 23|8@0+ (2,597) [0|255] "mbar" XXX
 SG_ MULTIPLEXD_MSG : 7|8@0+ (1,0) [0|255] "" XXX
 SG_ COOLANT_TEMP : 15|8@0+ (0.75,-48) [0|255] "" XXX
 SG_ CRUISE_I_O : 31|1@0+ (1,0) [0|1] "" XXX
 SG_ CRUISE_AC_DECELARATION : 53|2@0+ (1,0) [0|3] "" XXX
 SG_ NEW_SIGNAL : 25|1@1+ (1,0) [0|3] "" XXX
 SG_ KICK_DOWN : 50|1@0+ (1,0) [0|1] "" XXX
 SG_ GAS_PEDAL : 47|8@0+ (0.005,0) [0|1] "" XXX
 SG_ CRUISE_CONTROL_UP : 29|1@0+ (1,0) [0|1] "" XXX
 SG_ CRUISE_CONTROL_DOWN : 30|1@0+ (1,0) [0|1] "" XXX
 SG_ RESUME_BTN : 30|2@0+ (1,0) [0|3] "" XXX

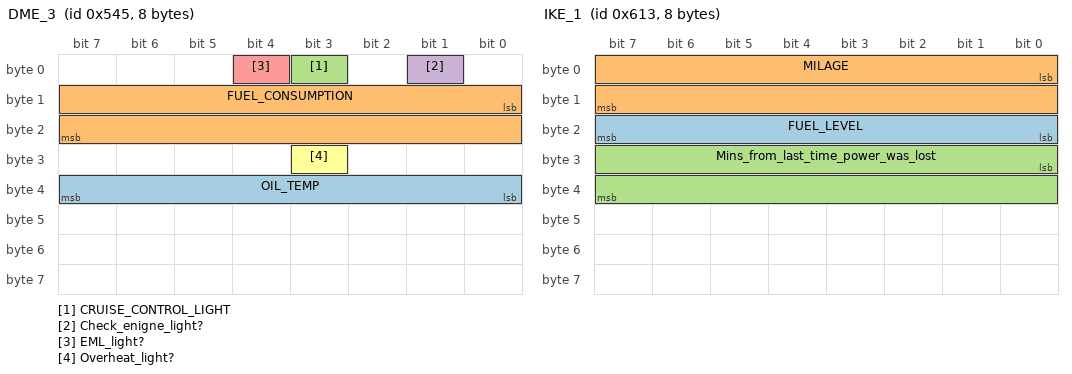
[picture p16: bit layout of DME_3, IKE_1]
BO_ 1349 DME_3: 8 XXX
 SG_ OIL_TEMP : 39|8@0+ (1,-48) [0|255] "" XXX
 SG_ FUEL_CONSUMPTION : 8|16@1+ (1,0) [0|255] "" XXX
 SG_ CRUISE_CONTROL_LIGHT : 3|1@0+ (1,0) [0|1] "" XXX
 SG_ Check_enigne_light? : 1|1@0+ (1,0) [0|1] "" XXX
 SG_ EML_light? : 4|1@0+ (1,0) [0|1] "" XXX
 SG_ Overheat_light? : 27|1@0+ (1,0) [0|3] "" XXX

BO_ 1555 IKE_1: 8 XXX
 SG_ FUEL_LEVEL : 23|8@0+ (1,0) [0|255] "" XXX
 SG_ MILAGE : 0|16@1+ (10,0) [0|65535] "" XXX
 SG_ Mins_from_last_time_power_was_lost : 24|16@1+ (1,0) [0|65535] "" XXX

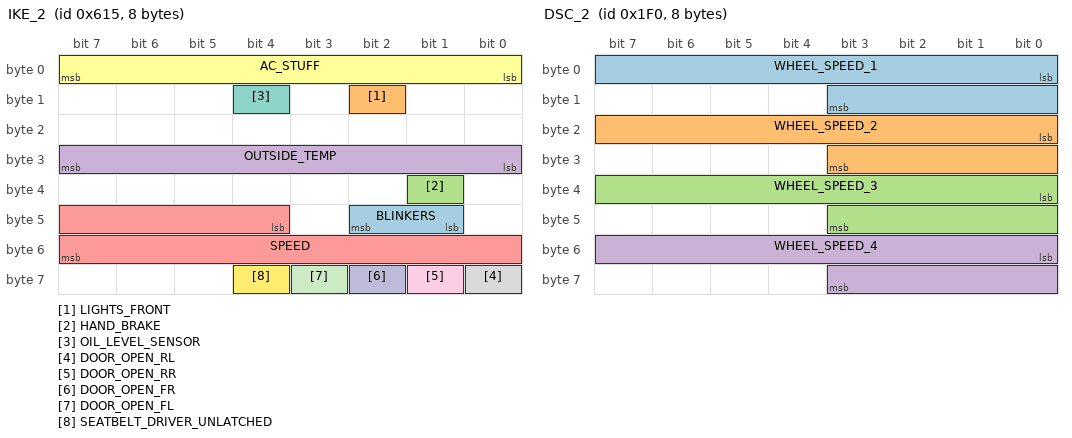
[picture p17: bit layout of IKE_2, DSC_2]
BO_ 1557 IKE_2: 8 XXX
 SG_ BLINKERS : 42|2@0+ (1,0) [0|3] "" XXX
 SG_ LIGHTS_FRONT : 10|1@1+ (1,0) [0|3] "" XXX
 SG_ HAND_BRAKE : 33|1@1+ (1,0) [0|3] "" XXX
 SG_ OUTSIDE_TEMP : 31|8@0+ (1,0) [0|255] "°C" XXX
 SG_ SPEED : 44|12@1+ (0.11,0) [0|4095] "kph" XXX
 SG_ AC_STUFF : 7|8@0+ (1,0) [0|31] "" XXX
 SG_ OIL_LEVEL_SENSOR : 12|1@0+ (1,0) [0|1] "" XXX
 SG_ DOOR_OPEN_RL : 56|1@0+ (1,0) [0|1] "" XXX
 SG_ DOOR_OPEN_RR : 57|1@0+ (1,0) [0|1] "" XXX
 SG_ DOOR_OPEN_FR : 58|1@0+ (1,0) [0|1] "" XXX
 SG_ DOOR_OPEN_FL : 59|1@0+ (1,0) [0|1] "" XXX
 SG_ SEATBELT_DRIVER_UNLATCHED : 60|1@0+ (1,0) [0|1] "" XXX

BO_ 496 DSC_2: 8 XXX
 SG_ WHEEL_SPEED_1 : 0|12@1+ (0.0625,-2.64) [0|4095] "km/h" XXX
 SG_ WHEEL_SPEED_2 : 16|12@1+ (0.0625,-2.64) [0|4095] "km/h" XXX
 SG_ WHEEL_SPEED_3 : 32|12@1+ (0.0625,-2.64) [0|4095] "km/h" XXX
 SG_ WHEEL_SPEED_4 : 48|12@1+ (0.0625,-2.64) [0|4095] "km/h" XXX

BO_ 499 DSC_3: 8 XXX
 SG_ LATERAL_ACCELERATION : 0|16@1- (1,0) [0|65535] "" XXX
 SG_ LONGITUDINAL_ACCELERATION : 16|16@1- (1,0) [0|65535] "" XXX

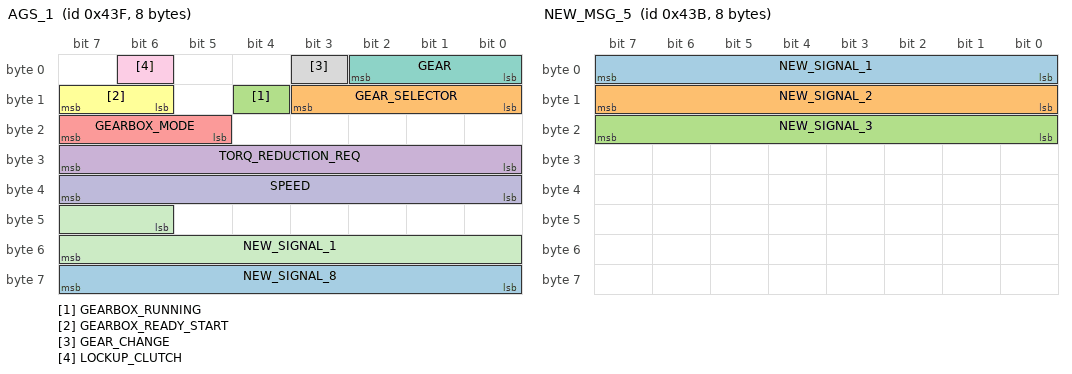
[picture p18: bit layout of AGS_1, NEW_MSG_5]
BO_ 1087 AGS_1: 8 XXX
 SG_ NEW_SIGNAL_8 : 63|8@0+ (1,0) [0|1] "" XXX
 SG_ GEAR_SELECTOR : 11|4@0+ (1,0) [0|1] "" XXX
 SG_ GEARBOX_RUNNING : 12|1@0+ (1,0) [0|3] "" XXX
 SG_ TORQ_REDUCTION_REQ : 31|8@0+ (1,0) [0|255] "" XXX
 SG_ GEARBOX_MODE : 23|3@0+ (1,0) [0|1] "" XXX
 SG_ GEARBOX_READY_START : 15|2@0+ (1,0) [0|1] "" XXX
 SG_ GEAR : 0|3@1+ (1,0) [0|7] "" XXX
 SG_ GEAR_CHANGE : 3|1@1+ (1,0) [0|7] "" XXX
 SG_ LOCKUP_CLUTCH : 6|1@0+ (1,0) [0|3] "" XXX
 SG_ SPEED : 39|8@0+ (1.37,0) [0|1] "" XXX
 SG_ NEW_SIGNAL_1 : 46|10@1+ (1,0) [0|255] "" XXX

BO_ 1916 NEW_MSG_2: 8 XXX
 SG_ ACCELEROMETER : 16|16@1- (1,0) [0|1] "" XXX

BO_ 1919 NEW_MSG_3: 8 XXX
 SG_ BRAKE_PRESSURE : 48|16@1+ (0.025,0) [0|65535] "" XXX

BO_ 1973 NEW_MSG_4: 8 XXX

BO_ 1083 NEW_MSG_5: 8 XXX
 SG_ NEW_SIGNAL_1 : 7|8@0+ (1,0) [0|1] "" XXX
 SG_ NEW_SIGNAL_2 : 15|8@0+ (1,0) [0|1] "" XXX
 SG_ NEW_SIGNAL_3 : 23|8@0+ (1,0) [0|1] "" XXX

CM_ SG_ 501 VELOCITY_DIRECTION "0 is left and 1 is right";
CM_ SG_ 501 ANGLE_DIRECTION "0 is left and 1 is right";
CM_ SG_ 809 RESUME_BTN "1 is UP 2 is DOWN and 3 is RESUME";
CM_ SG_ 1349 Check_enigne_light? "Goes to zero right afer startup";
CM_ SG_ 1349 EML_light? "Goes to zero right after ignition activation";
CM_ SG_ 1555 FUEL_LEVEL "In liters";
CM_ SG_ 496 WHEEL_SPEED_1 "raw wheel speed";
CM_ SG_ 496 WHEEL_SPEED_2 "raw wheel speed";
CM_ SG_ 496 WHEEL_SPEED_3 "raw wheel speed";
CM_ SG_ 496 WHEEL_SPEED_4 "raw wheel speed";

CM_ "toyota_corolla_2017_pt.dbc starts here";

BO_ 548 BRAKE_MODULE: 8 XXX
 SG_ BRAKE_PRESSURE : 43|12@0+ (1,0) [0|4047] "" XXX
 SG_ BRAKE_PRESSED : 5|1@0+ (1,0) [0|1] "" XXX

BO_ 705 GAS_PEDAL: 8 XXX
 SG_ GAS_RELEASED : 3|1@0+ (1,0) [0|1] "" XXX
 SG_ GAS_PEDAL : 55|8@0+ (0.005,0) [0|1] "" XXX

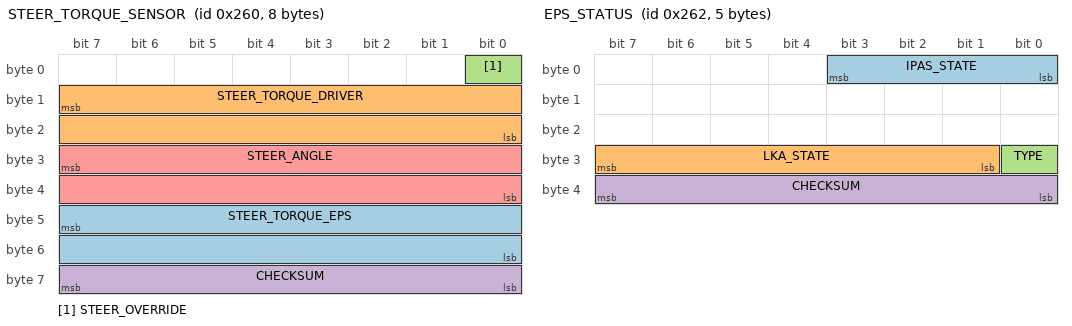
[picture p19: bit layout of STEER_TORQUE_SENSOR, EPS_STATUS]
BO_ 608 STEER_TORQUE_SENSOR: 8 XXX
 SG_ STEER_TORQUE_EPS : 47|16@0- (0.88,0) [-20000|20000] "" XXX
 SG_ STEER_TORQUE_DRIVER : 15|16@0- (1,0) [-32768|32767] "" XXX
 SG_ STEER_OVERRIDE : 0|1@0+ (1,0) [0|1] "" XXX
 SG_ CHECKSUM : 63|8@0+ (1,0) [0|255] "" XXX
 SG_ STEER_ANGLE : 31|16@0- (0.0573,0) [-500|500] "" XXX

BO_ 610 EPS_STATUS: 5 EPS
 SG_ IPAS_STATE : 3|4@0+ (1,0) [0|15] "" XXX
 SG_ LKA_STATE : 31|7@0+ (1,0) [0|127] "" XXX
 SG_ TYPE : 24|1@0+ (1,0) [0|1] "" XXX
 SG_ CHECKSUM : 39|8@0+ (1,0) [0|255] "" XXX

BO_ 956 GEAR_PACKET: 8 XXX
 SG_ GEAR : 13|6@0+ (1,0) [0|63] "" XXX
 SG_ SPORT_ON : 3|1@0+ (1,0) [0|1] "" XXX

CM_ SG_ 548 BRAKE_PRESSURE "seems prop to pedal force";
CM_ SG_ 548 BRAKE_POSITION "seems proportional to pedal displacement, unclear the max value of 0x1c8";
CM_ SG_ 610 TYPE "seems 1 on Corolla, 0 on all others";
VAL_ 956 GEAR 0 "D" 1 "S" 8 "N" 16 "R" 32 "P";
VAL_ 610 IPAS_STATE 5 "override" 3 "enabled" 1 "disabled";
VAL_ 610 LKA_STATE 25 "temporary_fault" 9 "temporary_fault2" 5 "active" 1 "standby";
